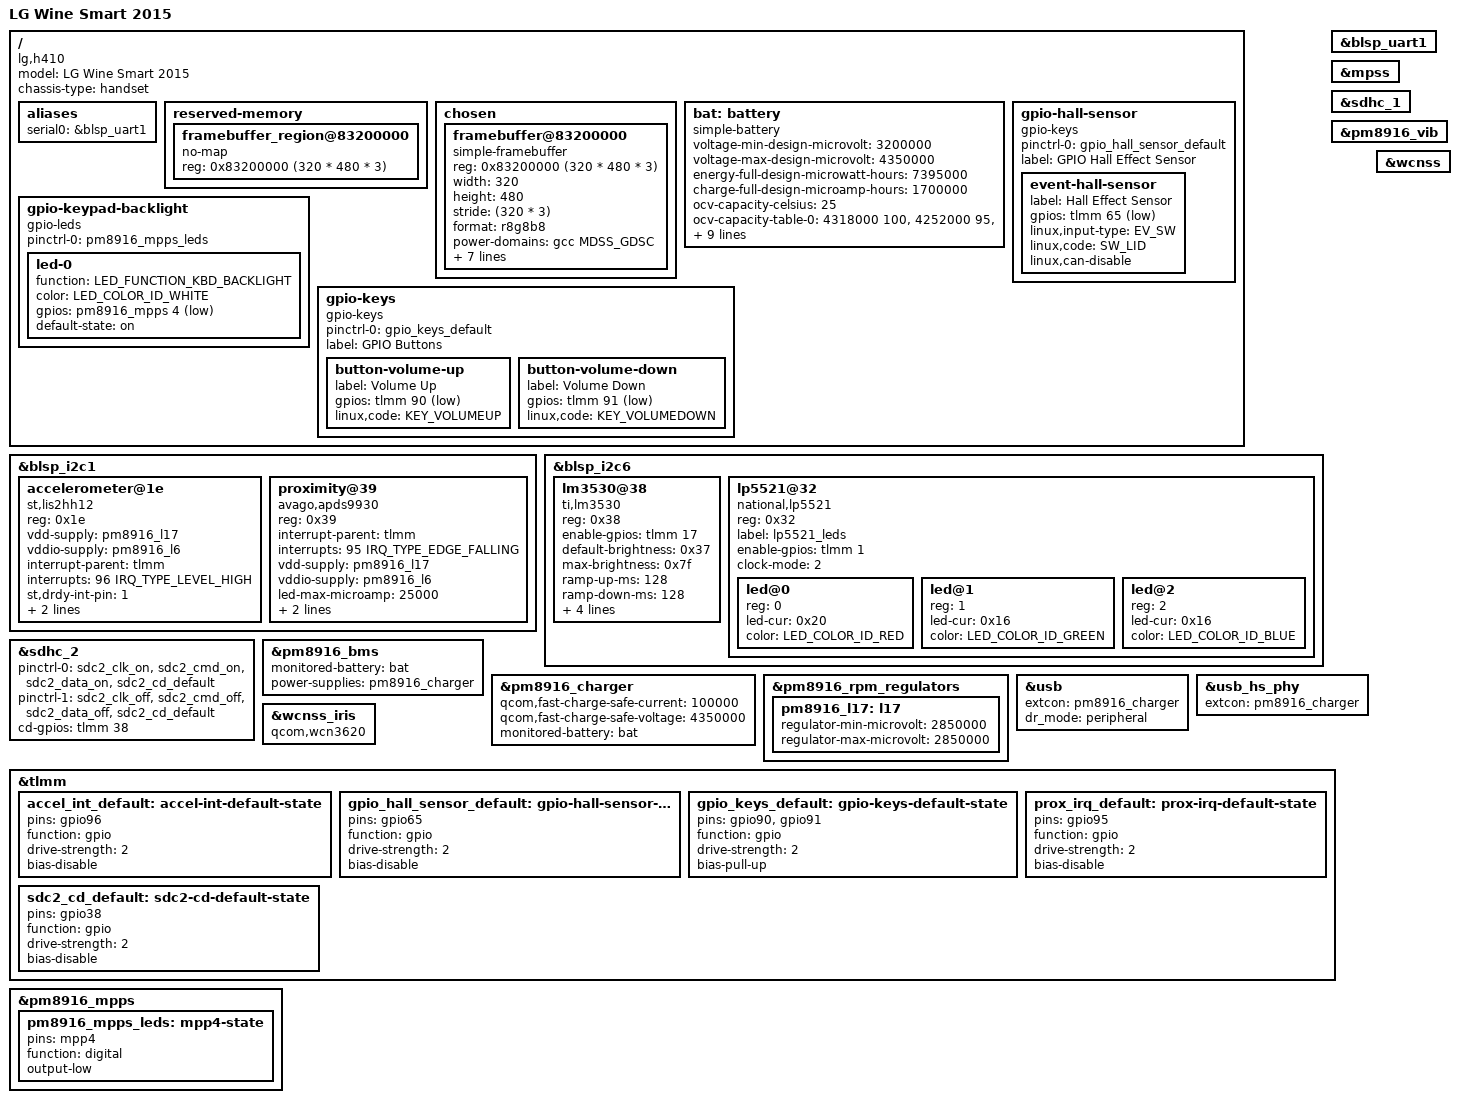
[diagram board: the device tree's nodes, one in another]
// SPDX-License-Identifier: GPL-2.0-only

/dts-v1/;

#include "qcom-msm8909-pm8916.dtsi"

#include <dt-bindings/gpio/gpio.h>
#include <dt-bindings/input/input.h>
#include <dt-bindings/interrupt-controller/irq.h>
#include <dt-bindings/leds/common.h>
#include <dt-bindings/pinctrl/qcom,pmic-mpp.h>

/ {
	model = "LG Wine Smart 2015";
	compatible = "lg,h410", "qcom,msm8909";
	chassis-type = "handset";

	aliases {
		serial0 = &blsp_uart1;
	};

	reserved-memory {
		#address-cells = <1>;
		#size-cells = <1>;
		ranges;

		framebuffer_region@83200000 {
			no-map;
			reg = <0x83200000 (320 * 480 * 3)>;
		};
	};

	chosen {
		#address-cells = <1>;
		#size-cells = <1>;
		ranges;

		framebuffer@83200000 {
			compatible = "simple-framebuffer";
			reg = <0x83200000 (320 * 480 * 3)>;

			width = <320>;
			height = <480>;
			stride = <(320 * 3)>;
			format = "r8g8b8";

			power-domains = <&gcc MDSS_GDSC>;

			clocks = <&gcc GCC_MDSS_AHB_CLK>,
				 <&gcc GCC_MDSS_AXI_CLK>,
				 <&gcc GCC_MDSS_VSYNC_CLK>,
				 <&gcc GCC_MDSS_MDP_CLK>,
				 <&gcc GCC_MDSS_BYTE0_CLK>,
				 <&gcc GCC_MDSS_PCLK0_CLK>,
				 <&gcc GCC_MDSS_ESC0_CLK>;
		};
	};

	bat: battery {
		compatible = "simple-battery";
		voltage-min-design-microvolt = <3200000>;
		voltage-max-design-microvolt = <4350000>;
		energy-full-design-microwatt-hours = <7395000>;
		charge-full-design-microamp-hours = <1700000>;

		ocv-capacity-celsius = <25>;
		ocv-capacity-table-0 = <4318000 100>, <4252000 95>, <4198000 90>,
			<4146000 85>, <4097000 80>, <4052000 75>, <4005000 70>,
			<3960000 65>, <3907000 60>, <3872000 55>, <3844000 50>,
			<3822000 45>, <3801000 40>, <3783000 35>, <3756000 30>,
			<3716000 25>, <3692000 20>, <3681000 16>, <3644000 13>,
			<3606000 11>, <3584000 10>, <3555000 9>, <3523000 8>,
			<3490000 7>, <3458000 6>, <3426000 5>, <3387000 4>,
			<3339000 3>, <3274000 2>, <3178000 1>, <3000000 0>;
	};

	gpio-hall-sensor {
		compatible = "gpio-keys";

		pinctrl-0 = <&gpio_hall_sensor_default>;
		pinctrl-names = "default";

		label = "GPIO Hall Effect Sensor";

		event-hall-sensor {
			label = "Hall Effect Sensor";
			gpios = <&tlmm 65 GPIO_ACTIVE_LOW>;
			linux,input-type = <EV_SW>;
			linux,code = <SW_LID>;
			linux,can-disable;
		};
	};

	gpio-keypad-backlight {
		pinctrl-0 = <&pm8916_mpps_leds>;
		pinctrl-names = "default";

		compatible = "gpio-leds";

		led-0 {
			function = LED_FUNCTION_KBD_BACKLIGHT;
			color = <LED_COLOR_ID_WHITE>;
			gpios = <&pm8916_mpps 4 GPIO_ACTIVE_LOW>;
			default-state = "on";
		};
	};

	gpio-keys {
		compatible = "gpio-keys";

		pinctrl-0 = <&gpio_keys_default>;
		pinctrl-names = "default";

		label = "GPIO Buttons";

		button-volume-up {
			label = "Volume Up";
			gpios = <&tlmm 90 GPIO_ACTIVE_LOW>;
			linux,code = <KEY_VOLUMEUP>;
		};

		button-volume-down {
			label = "Volume Down";
			gpios = <&tlmm 91 GPIO_ACTIVE_LOW>;
			linux,code = <KEY_VOLUMEDOWN>;
		};
	};

};

&blsp_i2c1 {
	status = "okay";

	accelerometer@1e {
		compatible = "st,lis2hh12";
		reg = <0x1e>;

		vdd-supply = <&pm8916_l17>;
		vddio-supply = <&pm8916_l6>;

		interrupt-parent = <&tlmm>;
		interrupts = <96 IRQ_TYPE_LEVEL_HIGH>;

		st,drdy-int-pin = <1>;
		mount-matrix = "-1", "0", "0",
			      "0", "-1", "0",
			       "0", "0", "-1";

		pinctrl-0 = <&accel_int_default>;
		pinctrl-names = "default";
	};

	proximity@39 {
		/* APDS-9130 */
		compatible = "avago,apds9930";
		reg = <0x39>;

		interrupt-parent = <&tlmm>;
		interrupts = <95 IRQ_TYPE_EDGE_FALLING>;

		vdd-supply = <&pm8916_l17>;
		vddio-supply = <&pm8916_l6>;

		led-max-microamp = <25000>;
		amstaos,proximity-diodes = <0>;

		pinctrl-0 = <&prox_irq_default>;
		pinctrl-names = "default";
	};
};

&blsp_i2c6 {
	status = "okay";

	lm3530@38 {
		compatible = "ti,lm3530";
		reg = <0x38>;

		enable-gpios = <&tlmm 17 GPIO_ACTIVE_HIGH>;
		default-brightness = /bits/ 8 <0x37>;
		max-brightness = /bits/ 8 <0x7f>;
		ramp-up-ms = <128>;
		ramp-down-ms = <128>;
		ti,current-limit = /bits/ 8 <0x9>;
		ti,led-mode = /bits/ 8 <0x00>; // PWM mode, Casio driver also do not touch ALS register
		ti,linear-mapping-mode = /bits/ 8 <1>;
		ti,no-regulator;
	};

	lp5521@32 {
		compatible = "national,lp5521";
		reg = <0x32>;
		label = "lp5521_leds";
		enable-gpios = <&tlmm 1 GPIO_ACTIVE_HIGH>;
		clock-mode = /bits/ 8 <2>;
		#address-cells = <1>;
		#size-cells = <0>;
		led@0 {
			reg = <0>;
			led-cur = /bits/ 8 <0x20>;
			color = <LED_COLOR_ID_RED>;
		};
		led@1 {
			reg = <1>;
			led-cur = /bits/ 8 <0x16>;
			color = <LED_COLOR_ID_GREEN>;
		};
		led@2 {
			reg = <2>;
			led-cur = /bits/ 8 <0x16>;
			color = <LED_COLOR_ID_BLUE>;
		};
	};
};

&blsp_uart1 {
	status = "okay";
};

&mpss {
	status = "okay";
};

&sdhc_1 {
	status = "okay";
};

&sdhc_2 {
	pinctrl-0 = <&sdc2_clk_on &sdc2_cmd_on &sdc2_data_on &sdc2_cd_default>;
	pinctrl-1 = <&sdc2_clk_off &sdc2_cmd_off &sdc2_data_off &sdc2_cd_default>;
	pinctrl-names = "default", "sleep";

	cd-gpios = <&tlmm 38 GPIO_ACTIVE_HIGH>;

	status = "okay";
};

&pm8916_bms {
	monitored-battery = <&bat>;
	power-supplies = <&pm8916_charger>;

	status = "okay";
};

&pm8916_charger {
	qcom,fast-charge-safe-current = <100000>;
	qcom,fast-charge-safe-voltage = <4350000>;

	monitored-battery = <&bat>;
	status = "okay";
};

&pm8916_rpm_regulators {
	pm8916_l17: l17 {
		regulator-min-microvolt = <2850000>;
		regulator-max-microvolt = <2850000>;
	};
};

&pm8916_vib {
	status = "okay";
};

&usb {
	extcon = <&pm8916_charger>;
	dr_mode = "peripheral";
	status = "okay";
};

&usb_hs_phy {
	extcon = <&pm8916_charger>;
};

&wcnss {
	status = "okay";
};

&wcnss_iris {
	compatible = "qcom,wcn3620";
};

&tlmm {
	accel_int_default: accel-int-default-state {
		pins = "gpio96";
		function = "gpio";
		drive-strength = <2>;
		bias-disable;
	};

	gpio_hall_sensor_default: gpio-hall-sensor-default-state {
		pins = "gpio65";
		function = "gpio";
		drive-strength = <2>;
		bias-disable;
	};

	gpio_keys_default: gpio-keys-default-state {
		pins = "gpio90", "gpio91";
		function = "gpio";
		drive-strength = <2>;
		bias-pull-up;
	};

	prox_irq_default: prox-irq-default-state {
		pins = "gpio95";
		function = "gpio";
		drive-strength = <2>;
		bias-disable;
	};

	sdc2_cd_default: sdc2-cd-default-state {
		pins = "gpio38";
		function = "gpio";
		drive-strength = <2>;
		bias-disable;
	};
};

&pm8916_mpps {
	pm8916_mpps_leds: mpp4-state {
		pins = "mpp4";
		function = "digital";
		output-low;
	};
};
